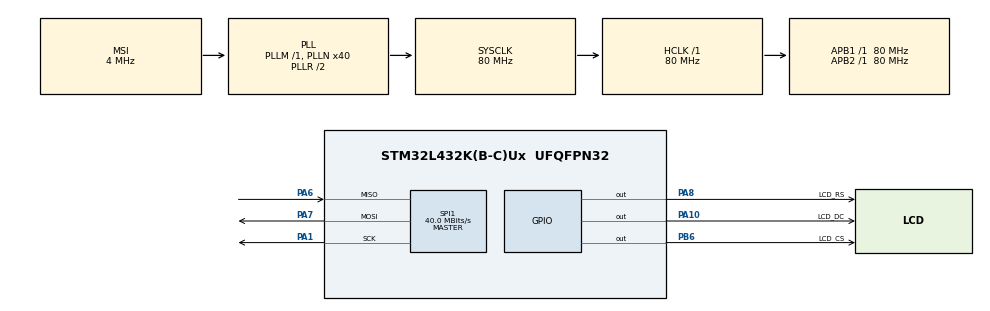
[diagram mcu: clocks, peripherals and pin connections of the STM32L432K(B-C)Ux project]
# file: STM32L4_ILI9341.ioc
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Mcu.Family=STM32L4
Mcu.Name=STM32L432K(B-C)Ux
Mcu.Package=UFQFPN32
NVIC.PriorityGroup=NVIC_PRIORITYGROUP_4
PA1.Mode=Full_Duplex_Master
PA1.Signal=SPI1_SCK
PA10.GPIO_Label=LCD_DC
PA10.Signal=GPIO_Output
PA6.Mode=Full_Duplex_Master
PA6.Signal=SPI1_MISO
PA7.Mode=Full_Duplex_Master
PA7.Signal=SPI1_MOSI
PA8.GPIO_Label=LCD_RS
PA8.Signal=GPIO_Output
PB6.GPIO_Label=LCD_CS
PB6.Signal=GPIO_Output
ProjectManager.HeapSize=0x200
ProjectManager.StackSize=0x400
ProjectManager.TargetToolchain=SW4STM32
RCC.AHBFreq_Value=80000000
RCC.APB1Freq_Value=80000000
RCC.APB1TimFreq_Value=80000000
RCC.APB2Freq_Value=80000000
RCC.APB2TimFreq_Value=80000000
RCC.CortexFreq_Value=80000000
RCC.HCLKFreq_Value=80000000
RCC.HSE_VALUE=8000000
RCC.HSI16_VALUE=16000000
RCC.HSI48_VALUE=48000000
RCC.HSI_VALUE=16000000
RCC.LSE_VALUE=32768
RCC.MSI_VALUE=4000000
RCC.PLLMUL=RCC_PLLMUL_4
RCC.PLLN=40
RCC.SYSCLKFreq_VALUE=80000000
RCC.SYSCLKSource=RCC_SYSCLKSOURCE_PLLCLK
RCC.VCOOutputFreq_Value=160000000
SPI1.CalculateBaudRate=40.0 MBits/s
SPI1.DataSize=SPI_DATASIZE_8BIT
SPI1.Direction=SPI_DIRECTION_2LINES
SPI1.Mode=SPI_MODE_MASTER
SPI1.VirtualType=VM_MASTER
board=NUCLEO-L432KC

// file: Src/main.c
/* USER CODE BEGIN Header */
/**
  ******************************************************************************
  * @file           : main.c
  * @brief          : Main program body
  ******************************************************************************
  ** This notice applies to any and all portions of this file
  * that are not between comment pairs USER CODE BEGIN and
  * USER CODE END. Other portions of this file, whether
  * inserted by the user or by software development tools
  * are owned by their respective copyright owners.
  *
  * COPYRIGHT(c) 2019 STMicroelectronics
  *
  * Redistribution and use in source and binary forms, with or without modification,
  * are permitted provided that the following conditions are met:
  *   1. Redistributions of source code must retain the above copyright notice,
  *      this list of conditions and the following disclaimer.
  *   2. Redistributions in binary form must reproduce the above copyright notice,
  *      this list of conditions and the following disclaimer in the documentation
  *      and/or other materials provided with the distribution.
  *   3. Neither the name of STMicroelectronics nor the names of its contributors
  *      may be used to endorse or promote products derived from this software
  *      without specific prior written permission.
  *
  * THIS SOFTWARE IS PROVIDED BY THE COPYRIGHT HOLDERS AND CONTRIBUTORS "AS IS"
  * AND ANY EXPRESS OR IMPLIED WARRANTIES, INCLUDING, BUT NOT LIMITED TO, THE
  * IMPLIED WARRANTIES OF MERCHANTABILITY AND FITNESS FOR A PARTICULAR PURPOSE ARE
  * DISCLAIMED. IN NO EVENT SHALL THE COPYRIGHT HOLDER OR CONTRIBUTORS BE LIABLE
  * FOR ANY DIRECT, INDIRECT, INCIDENTAL, SPECIAL, EXEMPLARY, OR CONSEQUENTIAL
  * DAMAGES (INCLUDING, BUT NOT LIMITED TO, PROCUREMENT OF SUBSTITUTE GOODS OR
  * SERVICES; LOSS OF USE, DATA, OR PROFITS; OR BUSINESS INTERRUPTION) HOWEVER
  * CAUSED AND ON ANY THEORY OF LIABILITY, WHETHER IN CONTRACT, STRICT LIABILITY,
  * OR TORT (INCLUDING NEGLIGENCE OR OTHERWISE) ARISING IN ANY WAY OUT OF THE USE
  * OF THIS SOFTWARE, EVEN IF ADVISED OF THE POSSIBILITY OF SUCH DAMAGE.
  *
  ******************************************************************************
  */
/* USER CODE END Header */

#include "main.h"

/* USER CODE BEGIN Includes */
#include "ILI9341.h"
/* USER CODE END Includes */

SPI_HandleTypeDef hspi1;

void SystemClock_Config(void);
static void MX_GPIO_Init(void);
static void MX_SPI1_Init(void);

int main(void)
{

  /* MCU Configuration--------------------------------------------------------*/

  /* Reset of all peripherals, Initializes the Flash interface and the Systick. */
  HAL_Init();

  /* Configure the system clock */
  SystemClock_Config();

  /* Initialize all configured peripherals */
  MX_GPIO_Init();
  MX_SPI1_Init();
  /* USER CODE BEGIN 2 */

  ILI9341_Init(&hspi1, LCD_CS_Pin, LCD_CS_GPIO_Port, LCD_DC_Pin, LCD_DC_GPIO_Port, LCD_RS_Pin, LCD_RS_GPIO_Port);
  /* USER CODE END 2 */

  /* Infinite loop */
  while (1)
  {

  }
}

void SystemClock_Config(void)
{
  RCC_OscInitTypeDef RCC_OscInitStruct = {0};
  RCC_ClkInitTypeDef RCC_ClkInitStruct = {0};

  /**Initializes the CPU, AHB and APB busses clocks
  */
  RCC_OscInitStruct.OscillatorType = RCC_OSCILLATORTYPE_MSI;
  RCC_OscInitStruct.MSIState = RCC_MSI_ON;
  RCC_OscInitStruct.MSICalibrationValue = 0;
  RCC_OscInitStruct.MSIClockRange = RCC_MSIRANGE_6;
  RCC_OscInitStruct.PLL.PLLState = RCC_PLL_ON;
  RCC_OscInitStruct.PLL.PLLSource = RCC_PLLSOURCE_MSI;
  RCC_OscInitStruct.PLL.PLLM = 1;
  RCC_OscInitStruct.PLL.PLLN = 40;
  RCC_OscInitStruct.PLL.PLLP = RCC_PLLP_DIV7;
  RCC_OscInitStruct.PLL.PLLQ = RCC_PLLQ_DIV2;
  RCC_OscInitStruct.PLL.PLLR = RCC_PLLR_DIV2;
  if (HAL_RCC_OscConfig(&RCC_OscInitStruct) != HAL_OK)
  {
    Error_Handler();
  }
  /**Initializes the CPU, AHB and APB busses clocks
  */
  RCC_ClkInitStruct.ClockType = RCC_CLOCKTYPE_HCLK|RCC_CLOCKTYPE_SYSCLK
                              |RCC_CLOCKTYPE_PCLK1|RCC_CLOCKTYPE_PCLK2;
  RCC_ClkInitStruct.SYSCLKSource = RCC_SYSCLKSOURCE_PLLCLK;
  RCC_ClkInitStruct.AHBCLKDivider = RCC_SYSCLK_DIV1;
  RCC_ClkInitStruct.APB1CLKDivider = RCC_HCLK_DIV1;
  RCC_ClkInitStruct.APB2CLKDivider = RCC_HCLK_DIV1;

  if (HAL_RCC_ClockConfig(&RCC_ClkInitStruct, FLASH_LATENCY_4) != HAL_OK)
  {
    Error_Handler();
  }
  /**Configure the main internal regulator output voltage
  */
  if (HAL_PWREx_ControlVoltageScaling(PWR_REGULATOR_VOLTAGE_SCALE1) != HAL_OK)
  {
    Error_Handler();
  }
}

static void MX_SPI1_Init(void)
{

  /* SPI1 parameter configuration*/
  hspi1.Instance = SPI1;
  hspi1.Init.Mode = SPI_MODE_MASTER;
  hspi1.Init.Direction = SPI_DIRECTION_2LINES;
  hspi1.Init.DataSize = SPI_DATASIZE_8BIT;
  hspi1.Init.CLKPolarity = SPI_POLARITY_LOW;
  hspi1.Init.CLKPhase = SPI_PHASE_1EDGE;
  hspi1.Init.NSS = SPI_NSS_SOFT;
  hspi1.Init.BaudRatePrescaler = SPI_BAUDRATEPRESCALER_2;
  hspi1.Init.FirstBit = SPI_FIRSTBIT_MSB;
  hspi1.Init.TIMode = SPI_TIMODE_DISABLE;
  hspi1.Init.CRCCalculation = SPI_CRCCALCULATION_DISABLE;
  hspi1.Init.CRCPolynomial = 7;
  hspi1.Init.CRCLength = SPI_CRC_LENGTH_DATASIZE;
  hspi1.Init.NSSPMode = SPI_NSS_PULSE_ENABLE;
  if (HAL_SPI_Init(&hspi1) != HAL_OK)
  {
    Error_Handler();
  }

}

static void MX_GPIO_Init(void)
{
  GPIO_InitTypeDef GPIO_InitStruct = {0};

  /* GPIO Ports Clock Enable */
  __HAL_RCC_GPIOA_CLK_ENABLE();
  __HAL_RCC_GPIOB_CLK_ENABLE();

  /*Configure GPIO pin Output Level */
  HAL_GPIO_WritePin(GPIOA, LCD_RS_Pin|LCD_DC_Pin, GPIO_PIN_RESET);

  /*Configure GPIO pin Output Level */
  HAL_GPIO_WritePin(LCD_CS_GPIO_Port, LCD_CS_Pin, GPIO_PIN_RESET);

  /*Configure GPIO pins : LCD_RS_Pin LCD_DC_Pin */
  GPIO_InitStruct.Pin = LCD_RS_Pin|LCD_DC_Pin;
  GPIO_InitStruct.Mode = GPIO_MODE_OUTPUT_PP;
  GPIO_InitStruct.Pull = GPIO_NOPULL;
  GPIO_InitStruct.Speed = GPIO_SPEED_FREQ_LOW;
  HAL_GPIO_Init(GPIOA, &GPIO_InitStruct);

  /*Configure GPIO pin : LCD_CS_Pin */
  GPIO_InitStruct.Pin = LCD_CS_Pin;
  GPIO_InitStruct.Mode = GPIO_MODE_OUTPUT_PP;
  GPIO_InitStruct.Pull = GPIO_NOPULL;
  GPIO_InitStruct.Speed = GPIO_SPEED_FREQ_LOW;
  HAL_GPIO_Init(LCD_CS_GPIO_Port, &GPIO_InitStruct);

}

void Error_Handler(void)
{
}

/************************ (C) COPYRIGHT STMicroelectronics *****END OF FILE****/
